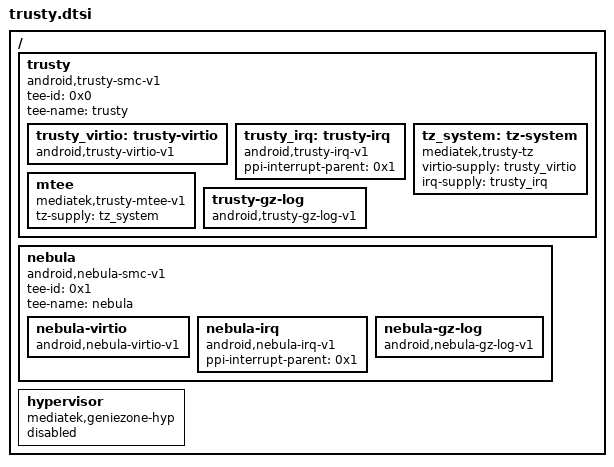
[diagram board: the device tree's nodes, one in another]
// SPDX-License-Identifier: GPL-2.0-only
/* MediaTek MT6781 GenieZone / Trusty / Nebula Virtualization bindings for Kernel 6.6 */

/ {
    trusty: trusty {
        compatible = "android,trusty-smc-v1";
        ranges;
        #address-cells = <0x2>;
        #size-cells = <0x2>;
        tee-id = <0x0>;
        tee-name = "trusty";
        trusty_virtio: trusty-virtio {
            compatible = "android,trusty-virtio-v1";
        };
        trusty_irq: trusty-irq {
            compatible = "android,trusty-irq-v1";
            ppi-interrupt-parent = <0x1>;
        };
        tz_system: tz-system {
            compatible = "mediatek,trusty-tz";
            virtio-supply = <&trusty_virtio>;
            irq-supply = <&trusty_irq>;
        };
        mtee: mtee {
            compatible = "mediatek,trusty-mtee-v1";
            tz-supply = <&tz_system>;
        };
        trusty-gz-log {
            compatible = "android,trusty-gz-log-v1";
        };
    };
    nebula: nebula {
        compatible = "android,nebula-smc-v1";
        ranges;
        #address-cells = <0x2>;
        #size-cells = <0x2>;
        tee-id = <0x1>;
        tee-name = "nebula";
        nebula-virtio {
            compatible = "android,nebula-virtio-v1";
        };
        nebula-irq {
            compatible = "android,nebula-irq-v1";
            ppi-interrupt-parent = <0x1>;
        };
        nebula-gz-log {
            compatible = "android,nebula-gz-log-v1";
        };
    };
    hypervisor: hypervisor {
        compatible = "mediatek,geniezone-hyp", "mediatek,geniezone";
        status = "disabled";
    };
};
